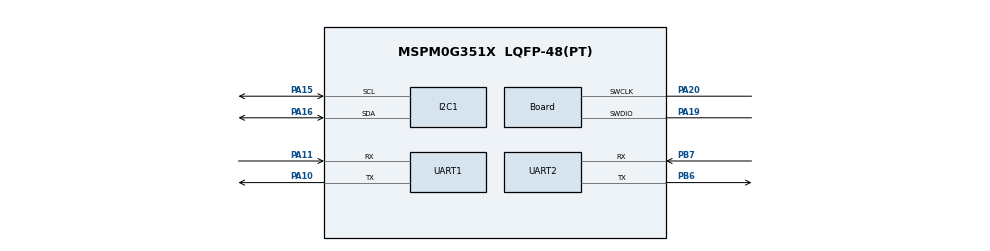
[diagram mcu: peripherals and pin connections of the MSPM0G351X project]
/**
 * @cliArgs --device "MSPM0G351X" --part "Default" --package "LQFP-48(PT)" --product "mspm0_sdk@2.02.00.05"
 * @versions {"tool":"1.21.1+3772"}
 */

/**
 * Import the modules used in this configuration.
 */
const I2C     = scripting.addModule("/ti/driverlib/I2C", {}, false);
const I2C1    = I2C.addInstance();
const SYSCTL  = scripting.addModule("/ti/driverlib/SYSCTL");
const SYSTICK = scripting.addModule("/ti/driverlib/SYSTICK");
const UART    = scripting.addModule("/ti/driverlib/UART", {}, false);
const UART1   = UART.addInstance();
const UART2   = UART.addInstance();

/**
 * Write custom configuration values to the imported modules.
 */
const gate7  = system.clockTree["MFCLKGATE"];
gate7.enable = true;

const multiplier2         = system.clockTree["PLL_QDIV"];
multiplier2.multiplyValue = 5;

I2C1.$name                             = "I2C_1";
I2C1.basicEnableController             = true;
I2C1.basicControllerStandardBusSpeed   = "Fast";
I2C1.peripheral.$assign                = "I2C1";
I2C1.peripheral.sdaPin.$assign         = "PA16";
I2C1.peripheral.sclPin.$assign         = "PA15";
I2C1.sdaPinConfig.hideOutputInversion  = scripting.forceWrite(false);
I2C1.sdaPinConfig.onlyInternalResistor = scripting.forceWrite(false);
I2C1.sdaPinConfig.passedPeripheralType = scripting.forceWrite("Digital");
I2C1.sdaPinConfig.$name                = "ti_driverlib_gpio_GPIOPinGeneric2";
I2C1.sclPinConfig.hideOutputInversion  = scripting.forceWrite(false);
I2C1.sclPinConfig.onlyInternalResistor = scripting.forceWrite(false);
I2C1.sclPinConfig.passedPeripheralType = scripting.forceWrite("Digital");
I2C1.sclPinConfig.$name                = "ti_driverlib_gpio_GPIOPinGeneric3";

const Board                       = scripting.addModule("/ti/driverlib/Board", {}, false);
Board.peripheral.$assign          = "DEBUGSS";
Board.peripheral.swclkPin.$assign = "PA20";
Board.peripheral.swdioPin.$assign = "PA19";

SYSCTL.forceDefaultClkConfig = true;
SYSCTL.clockTreeEn           = true;

SYSTICK.periodEnable  = true;
SYSTICK.systickEnable = true;
SYSTICK.period        = 32;

UART1.$name                    = "UART_0";
UART1.uartClkSrc               = "MFCLK";
UART1.enabledInterrupts        = ["RX"];
UART1.targetBaudRate           = 115200;
UART1.peripheral.$assign       = "UART0";
UART1.peripheral.rxPin.$assign = "PA11";
UART1.peripheral.txPin.$assign = "PA10";
UART1.txPinConfig.$name        = "ti_driverlib_gpio_GPIOPinGeneric0";
UART1.rxPinConfig.$name        = "ti_driverlib_gpio_GPIOPinGeneric1";

UART2.$name                             = "UART_1";
UART2.uartClkSrc                        = "MFCLK";
UART2.targetBaudRate                    = 115200;
UART2.enableFIFO                        = true;
UART2.rxFifoThreshold                   = "DL_UART_RX_FIFO_LEVEL_ONE_ENTRY";
UART2.txFifoThreshold                   = "DL_UART_TX_FIFO_LEVEL_3_4_EMPTY";
UART2.enabledDMATXTriggers              = "DL_UART_DMA_INTERRUPT_TX";
UART2.enabledInterrupts                 = ["DMA_DONE_TX","EOT_DONE"];
UART2.peripheral.$assign                = "UART1";
UART2.peripheral.rxPin.$assign          = "PB7";
UART2.peripheral.txPin.$assign          = "PB6";
UART2.txPinConfig.$name                 = "ti_driverlib_gpio_GPIOPinGeneric4";
UART2.rxPinConfig.$name                 = "ti_driverlib_gpio_GPIOPinGeneric5";
UART2.DMA_CHANNEL_TX.$name              = "DMA_CH0";
UART2.DMA_CHANNEL_TX.addressMode        = "b2f";
UART2.DMA_CHANNEL_TX.srcLength          = "BYTE";
UART2.DMA_CHANNEL_TX.dstLength          = "BYTE";
UART2.DMA_CHANNEL_TX.peripheral.$assign = "DMA_CH0";

const ProjectConfig              = scripting.addModule("/ti/project_config/ProjectConfig", {}, false);
ProjectConfig.migrationCondition = true;
